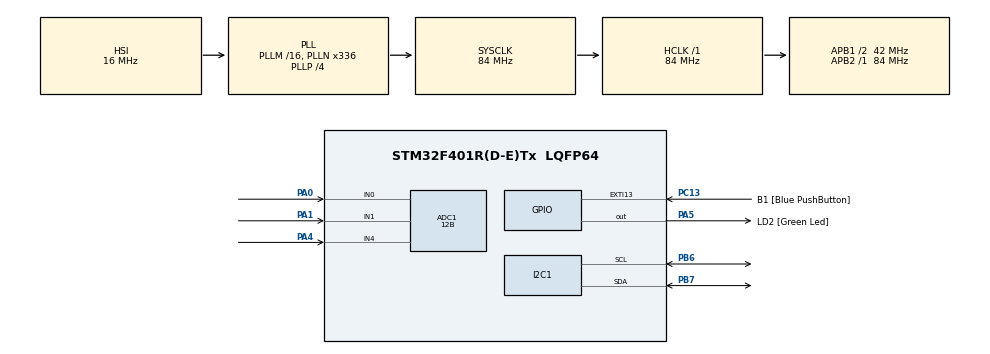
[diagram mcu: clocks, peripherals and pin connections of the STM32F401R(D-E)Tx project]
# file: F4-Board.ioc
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ADC1.Channel-17\#ChannelRegularConversion=ADC_CHANNEL_0
ADC1.Channel-20\#ChannelRegularConversion=ADC_CHANNEL_1
ADC1.Channel-21\#ChannelRegularConversion=ADC_CHANNEL_4
ADC1.ClockPrescaler=ADC_CLOCK_SYNC_PCLK_DIV4
ADC1.ContinuousConvMode=DISABLE
ADC1.DMAContinuousRequests=DISABLE
ADC1.DataAlign=ADC_DATAALIGN_RIGHT
ADC1.DiscontinuousConvMode=DISABLE
ADC1.EOCSelection=ADC_EOC_SINGLE_CONV
ADC1.EnableAnalogWatchDog=false
ADC1.ExternalTrigConvEdge=ADC_EXTERNALTRIGCONVEDGE_NONE
ADC1.InjNumberOfConversion=0
ADC1.NbrOfConversion=3
ADC1.NbrOfConversionFlag=1
ADC1.Rank-17\#ChannelRegularConversion=1
ADC1.Rank-20\#ChannelRegularConversion=2
ADC1.Rank-21\#ChannelRegularConversion=3
ADC1.Resolution=ADC_RESOLUTION_12B
ADC1.SamplingTime-17\#ChannelRegularConversion=ADC_SAMPLETIME_480CYCLES
ADC1.SamplingTime-20\#ChannelRegularConversion=ADC_SAMPLETIME_480CYCLES
ADC1.SamplingTime-21\#ChannelRegularConversion=ADC_SAMPLETIME_480CYCLES
ADC1.ScanConvMode=ENABLE
ADC1.master=1
I2C1.GeneralCallMode=I2C_GENERALCALL_ENABLE
I2C1.OwnAddress=12
Mcu.Family=STM32F4
Mcu.Name=STM32F401R(D-E)Tx
Mcu.Package=LQFP64
NVIC.I2C1_ER_IRQn=true\:0\:0\:false\:true\:true\:3
NVIC.I2C1_EV_IRQn=true\:0\:0\:true\:true\:true\:2
NVIC.PriorityGroup=NVIC_PRIORITYGROUP_0
NVIC.RCC_IRQn=true\:0\:0\:false\:true\:true\:1
PA0-WKUP.Signal=ADCx_IN0
PA1.Signal=ADCx_IN1
PA13.GPIO_Label=TMS
PA13.Signal=SYS_JTMS-SWDIO
PA14.GPIO_Label=TCK
PA14.Signal=SYS_JTCK-SWCLK
PA2.GPIO_Label=USART_TX
PA2.GPIO_Mode=GPIO_MODE_AF_PP
PA2.GPIO_PuPd=GPIO_NOPULL
PA2.GPIO_Speed=GPIO_SPEED_FREQ_LOW
PA2.Signal=USART2_TX
PA3.GPIO_Label=USART_RX
PA3.GPIO_Mode=GPIO_MODE_AF_PP
PA3.GPIO_PuPd=GPIO_NOPULL
PA3.GPIO_Speed=GPIO_SPEED_FREQ_LOW
PA3.Signal=USART2_RX
PA4.Signal=ADCx_IN4
PA5.GPIO_Label=LD2 [Green Led]
PA5.GPIO_Mode=GPIO_MODE_OUTPUT_PP
PA5.GPIO_PuPd=GPIO_NOPULL
PA5.GPIO_Speed=GPIO_SPEED_FREQ_LOW
PA5.Signal=GPIO_Output
PB3.GPIO_Label=SWO
PB3.Signal=SYS_JTDO-SWO
PB6.Mode=I2C
PB6.Signal=I2C1_SCL
PB7.Mode=I2C
PB7.Signal=I2C1_SDA
PC13-ANTI_TAMP.GPIO_Label=B1 [Blue PushButton]
PC13-ANTI_TAMP.GPIO_ModeDefaultEXTI=GPIO_MODE_EVT_RISING
PC13-ANTI_TAMP.GPIO_PuPd=GPIO_NOPULL
PC13-ANTI_TAMP.Signal=GPXTI13
PC14-OSC32_IN.Signal=RCC_OSC32_IN
PC15-OSC32_OUT.Signal=RCC_OSC32_OUT
PH0\ -\ OSC_IN.Signal=RCC_OSC_IN
PH1\ -\ OSC_OUT.Signal=RCC_OSC_OUT
ProjectManager.HeapSize=0x200
ProjectManager.StackSize=0x400
ProjectManager.TargetToolchain=MDK-ARM V5
RCC.AHBFreq_Value=84000000
RCC.APB1CLKDivider=RCC_HCLK_DIV2
RCC.APB1Freq_Value=42000000
RCC.APB1TimFreq_Value=84000000
RCC.APB2Freq_Value=84000000
RCC.APB2TimFreq_Value=84000000
RCC.CortexFreq_Value=84000000
RCC.HCLKFreq_Value=84000000
RCC.HSE_VALUE=8000000
RCC.HSI_VALUE=16000000
RCC.LSE_VALUE=32768
RCC.PLLN=336
RCC.PLLP=RCC_PLLP_DIV4
RCC.PLLQ=7
RCC.SYSCLKFreq_VALUE=84000000
RCC.SYSCLKSource=RCC_SYSCLKSOURCE_PLLCLK
RCC.VCOOutputFreq_Value=336000000
SH.ADCx_IN0.0=ADC1_IN0,IN0
SH.ADCx_IN1.0=ADC1_IN1,IN1
SH.ADCx_IN4.0=ADC1_IN4,IN4
board=NUCLEO-F401RE

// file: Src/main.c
/**
  ******************************************************************************
  * File Name          : main.c
  * Description        : Main program body
  ******************************************************************************
  *
  * COPYRIGHT(c) 2017 STMicroelectronics
  *
  * Redistribution and use in source and binary forms, with or without modification,
  * are permitted provided that the following conditions are met:
  *   1. Redistributions of source code must retain the above copyright notice,
  *      this list of conditions and the following disclaimer.
  *   2. Redistributions in binary form must reproduce the above copyright notice,
  *      this list of conditions and the following disclaimer in the documentation
  *      and/or other materials provided with the distribution.
  *   3. Neither the name of STMicroelectronics nor the names of its contributors
  *      may be used to endorse or promote products derived from this software
  *      without specific prior written permission.
  *
  * THIS SOFTWARE IS PROVIDED BY THE COPYRIGHT HOLDERS AND CONTRIBUTORS "AS IS"
  * AND ANY EXPRESS OR IMPLIED WARRANTIES, INCLUDING, BUT NOT LIMITED TO, THE
  * IMPLIED WARRANTIES OF MERCHANTABILITY AND FITNESS FOR A PARTICULAR PURPOSE ARE
  * DISCLAIMED. IN NO EVENT SHALL THE COPYRIGHT HOLDER OR CONTRIBUTORS BE LIABLE
  * FOR ANY DIRECT, INDIRECT, INCIDENTAL, SPECIAL, EXEMPLARY, OR CONSEQUENTIAL
  * DAMAGES (INCLUDING, BUT NOT LIMITED TO, PROCUREMENT OF SUBSTITUTE GOODS OR
  * SERVICES; LOSS OF USE, DATA, OR PROFITS; OR BUSINESS INTERRUPTION) HOWEVER
  * CAUSED AND ON ANY THEORY OF LIABILITY, WHETHER IN CONTRACT, STRICT LIABILITY,
  * OR TORT (INCLUDING NEGLIGENCE OR OTHERWISE) ARISING IN ANY WAY OUT OF THE USE
  * OF THIS SOFTWARE, EVEN IF ADVISED OF THE POSSIBILITY OF SUCH DAMAGE.
  *
  ******************************************************************************
  */
#include "main.h"
#include "stm32f4xx_hal.h"

ADC_HandleTypeDef hadc1;

I2C_HandleTypeDef hi2c1;

/* USER CODE BEGIN PV */
/* Private variables ---------------------------------------------------------*/

/* USER CODE END PV */

void SystemClock_Config(void);
void Error_Handler(void);
static void MX_GPIO_Init(void);
static void MX_I2C1_Init(void);
static void MX_ADC1_Init(void);
static void MX_NVIC_Init(void);

/* USER CODE BEGIN PFP */
/* Private function prototypes -----------------------------------------------*/

/* USER CODE END PFP */

/* USER CODE BEGIN 0 */
uint16_t ADC1_val[3];
uint8_t data[12];
uint16_t data2[6];
uint16_t temp;
/* USER CODE END 0 */

int main(void)
{

  /* MCU Configuration----------------------------------------------------------*/

  /* Reset of all peripherals, Initializes the Flash interface and the Systick. */
  HAL_Init();

  /* Configure the system clock */
  SystemClock_Config();

  /* Initialize all configured peripherals */
  MX_GPIO_Init();
  MX_I2C1_Init();
  MX_ADC1_Init();

  /* Initialize interrupts */
  MX_NVIC_Init();

  /* USER CODE BEGIN 2 */

		for(int i = 0; i < 5; i++){
      			HAL_GPIO_WritePin(LD2_GPIO_Port, LD2_Pin, GPIO_PIN_SET);
      			HAL_Delay(500);
      			HAL_GPIO_WritePin(LD2_GPIO_Port, LD2_Pin, GPIO_PIN_RESET);
      			HAL_Delay(500);
      		}
      		HAL_Delay(1000);

		while (HAL_I2C_GetState(&hi2c1) != HAL_I2C_STATE_READY)
		{
		}

		while(HAL_I2C_Slave_Receive_IT(&hi2c1, data , 12) != HAL_OK){
			Error_Handler();
		}

  /* USER CODE END 2 */

  /* Infinite loop */
		while (1)
  {

  }

}

void HAL_I2C_SlaveRxCpltCallback(I2C_HandleTypeDef *hi2c1)
{
	int a = 0;
	for(int i=0; i<=6;i++){
		data2[i] = (data[a]<<8) | data[a+1];
		a=a+2;
	}

	while (HAL_I2C_GetState(hi2c1) != HAL_I2C_STATE_READY)
	{
	}
	while(HAL_I2C_Slave_Receive_IT(hi2c1, data , 12) != HAL_OK){
			Error_Handler();
	}
}

/** System Clock Configuration
*/
void SystemClock_Config(void)
{

  RCC_OscInitTypeDef RCC_OscInitStruct;
  RCC_ClkInitTypeDef RCC_ClkInitStruct;

    /**Configure the main internal regulator output voltage
    */
  __HAL_RCC_PWR_CLK_ENABLE();

  __HAL_PWR_VOLTAGESCALING_CONFIG(PWR_REGULATOR_VOLTAGE_SCALE2);

    /**Initializes the CPU, AHB and APB busses clocks
    */
  RCC_OscInitStruct.OscillatorType = RCC_OSCILLATORTYPE_HSI;
  RCC_OscInitStruct.HSIState = RCC_HSI_ON;
  RCC_OscInitStruct.HSICalibrationValue = 16;
  RCC_OscInitStruct.PLL.PLLState = RCC_PLL_ON;
  RCC_OscInitStruct.PLL.PLLSource = RCC_PLLSOURCE_HSI;
  RCC_OscInitStruct.PLL.PLLM = 16;
  RCC_OscInitStruct.PLL.PLLN = 336;
  RCC_OscInitStruct.PLL.PLLP = RCC_PLLP_DIV4;
  RCC_OscInitStruct.PLL.PLLQ = 7;
  if (HAL_RCC_OscConfig(&RCC_OscInitStruct) != HAL_OK)
  {
    Error_Handler();
  }

    /**Initializes the CPU, AHB and APB busses clocks
    */
  RCC_ClkInitStruct.ClockType = RCC_CLOCKTYPE_HCLK|RCC_CLOCKTYPE_SYSCLK
                              |RCC_CLOCKTYPE_PCLK1|RCC_CLOCKTYPE_PCLK2;
  RCC_ClkInitStruct.SYSCLKSource = RCC_SYSCLKSOURCE_PLLCLK;
  RCC_ClkInitStruct.AHBCLKDivider = RCC_SYSCLK_DIV1;
  RCC_ClkInitStruct.APB1CLKDivider = RCC_HCLK_DIV2;
  RCC_ClkInitStruct.APB2CLKDivider = RCC_HCLK_DIV1;

  if (HAL_RCC_ClockConfig(&RCC_ClkInitStruct, FLASH_LATENCY_2) != HAL_OK)
  {
    Error_Handler();
  }

    /**Configure the Systick interrupt time
    */
  HAL_SYSTICK_Config(HAL_RCC_GetHCLKFreq()/1000);

    /**Configure the Systick
    */
  HAL_SYSTICK_CLKSourceConfig(SYSTICK_CLKSOURCE_HCLK);

  /* SysTick_IRQn interrupt configuration */
  HAL_NVIC_SetPriority(SysTick_IRQn, 0, 0);
}

/** NVIC Configuration
*/
static void MX_NVIC_Init(void)
{
  /* RCC_IRQn interrupt configuration */
  HAL_NVIC_SetPriority(RCC_IRQn, 0, 0);
  HAL_NVIC_EnableIRQ(RCC_IRQn);
  /* I2C1_EV_IRQn interrupt configuration */
  HAL_NVIC_SetPriority(I2C1_EV_IRQn, 0, 0);
  HAL_NVIC_EnableIRQ(I2C1_EV_IRQn);
  /* I2C1_ER_IRQn interrupt configuration */
  HAL_NVIC_SetPriority(I2C1_ER_IRQn, 0, 0);
  HAL_NVIC_EnableIRQ(I2C1_ER_IRQn);
}

/* ADC1 init function */
static void MX_ADC1_Init(void)
{

  ADC_ChannelConfTypeDef sConfig;

    /**Configure the global features of the ADC (Clock, Resolution, Data Alignment and number of conversion)
    */
  hadc1.Instance = ADC1;
  hadc1.Init.ClockPrescaler = ADC_CLOCK_SYNC_PCLK_DIV4;
  hadc1.Init.Resolution = ADC_RESOLUTION_12B;
  hadc1.Init.ScanConvMode = ENABLE;
  hadc1.Init.ContinuousConvMode = DISABLE;
  hadc1.Init.DiscontinuousConvMode = DISABLE;
  hadc1.Init.ExternalTrigConvEdge = ADC_EXTERNALTRIGCONVEDGE_NONE;
  hadc1.Init.DataAlign = ADC_DATAALIGN_RIGHT;
  hadc1.Init.NbrOfConversion = 3;
  hadc1.Init.DMAContinuousRequests = DISABLE;
  hadc1.Init.EOCSelection = ADC_EOC_SINGLE_CONV;
  if (HAL_ADC_Init(&hadc1) != HAL_OK)
  {
    Error_Handler();
  }

    /**Configure for the selected ADC regular channel its corresponding rank in the sequencer and its sample time.
    */
  sConfig.Channel = ADC_CHANNEL_0;
  sConfig.Rank = 1;
  sConfig.SamplingTime = ADC_SAMPLETIME_480CYCLES;
  if (HAL_ADC_ConfigChannel(&hadc1, &sConfig) != HAL_OK)
  {
    Error_Handler();
  }

    /**Configure for the selected ADC regular channel its corresponding rank in the sequencer and its sample time.
    */
  sConfig.Channel = ADC_CHANNEL_1;
  sConfig.Rank = 2;
  if (HAL_ADC_ConfigChannel(&hadc1, &sConfig) != HAL_OK)
  {
    Error_Handler();
  }

    /**Configure for the selected ADC regular channel its corresponding rank in the sequencer and its sample time.
    */
  sConfig.Channel = ADC_CHANNEL_4;
  sConfig.Rank = 3;
  if (HAL_ADC_ConfigChannel(&hadc1, &sConfig) != HAL_OK)
  {
    Error_Handler();
  }

}

/* I2C1 init function */
static void MX_I2C1_Init(void)
{

  hi2c1.Instance = I2C1;
  hi2c1.Init.ClockSpeed = 100000;
  hi2c1.Init.DutyCycle = I2C_DUTYCYCLE_2;
  hi2c1.Init.OwnAddress1 = 24;
  hi2c1.Init.AddressingMode = I2C_ADDRESSINGMODE_7BIT;
  hi2c1.Init.DualAddressMode = I2C_DUALADDRESS_DISABLE;
  hi2c1.Init.OwnAddress2 = 0;
  hi2c1.Init.GeneralCallMode = I2C_GENERALCALL_ENABLE;
  hi2c1.Init.NoStretchMode = I2C_NOSTRETCH_DISABLE;
  if (HAL_I2C_Init(&hi2c1) != HAL_OK)
  {
    Error_Handler();
  }

}

/** Configure pins as
        * Analog
        * Input
        * Output
        * EVENT_OUT
        * EXTI
     PA2   ------> USART2_TX
     PA3   ------> USART2_RX
*/
static void MX_GPIO_Init(void)
{

  GPIO_InitTypeDef GPIO_InitStruct;

  /* GPIO Ports Clock Enable */
  __HAL_RCC_GPIOC_CLK_ENABLE();
  __HAL_RCC_GPIOH_CLK_ENABLE();
  __HAL_RCC_GPIOA_CLK_ENABLE();
  __HAL_RCC_GPIOB_CLK_ENABLE();

  /*Configure GPIO pin : B1_Pin */
  GPIO_InitStruct.Pin = B1_Pin;
  GPIO_InitStruct.Mode = GPIO_MODE_EVT_RISING;
  GPIO_InitStruct.Pull = GPIO_NOPULL;
  HAL_GPIO_Init(B1_GPIO_Port, &GPIO_InitStruct);

  /*Configure GPIO pins : USART_TX_Pin USART_RX_Pin */
  GPIO_InitStruct.Pin = USART_TX_Pin|USART_RX_Pin;
  GPIO_InitStruct.Mode = GPIO_MODE_AF_PP;
  GPIO_InitStruct.Pull = GPIO_NOPULL;
  GPIO_InitStruct.Speed = GPIO_SPEED_FREQ_LOW;
  GPIO_InitStruct.Alternate = GPIO_AF7_USART2;
  HAL_GPIO_Init(GPIOA, &GPIO_InitStruct);

  /*Configure GPIO pin : LD2_Pin */
  GPIO_InitStruct.Pin = LD2_Pin;
  GPIO_InitStruct.Mode = GPIO_MODE_OUTPUT_PP;
  GPIO_InitStruct.Pull = GPIO_NOPULL;
  GPIO_InitStruct.Speed = GPIO_SPEED_FREQ_LOW;
  HAL_GPIO_Init(LD2_GPIO_Port, &GPIO_InitStruct);

  /*Configure GPIO pin Output Level */
  HAL_GPIO_WritePin(LD2_GPIO_Port, LD2_Pin, GPIO_PIN_RESET);

}

void Error_Handler(void)
{
  while(1)
  {
  }
}

/************************ (C) COPYRIGHT STMicroelectronics *****END OF FILE****/
